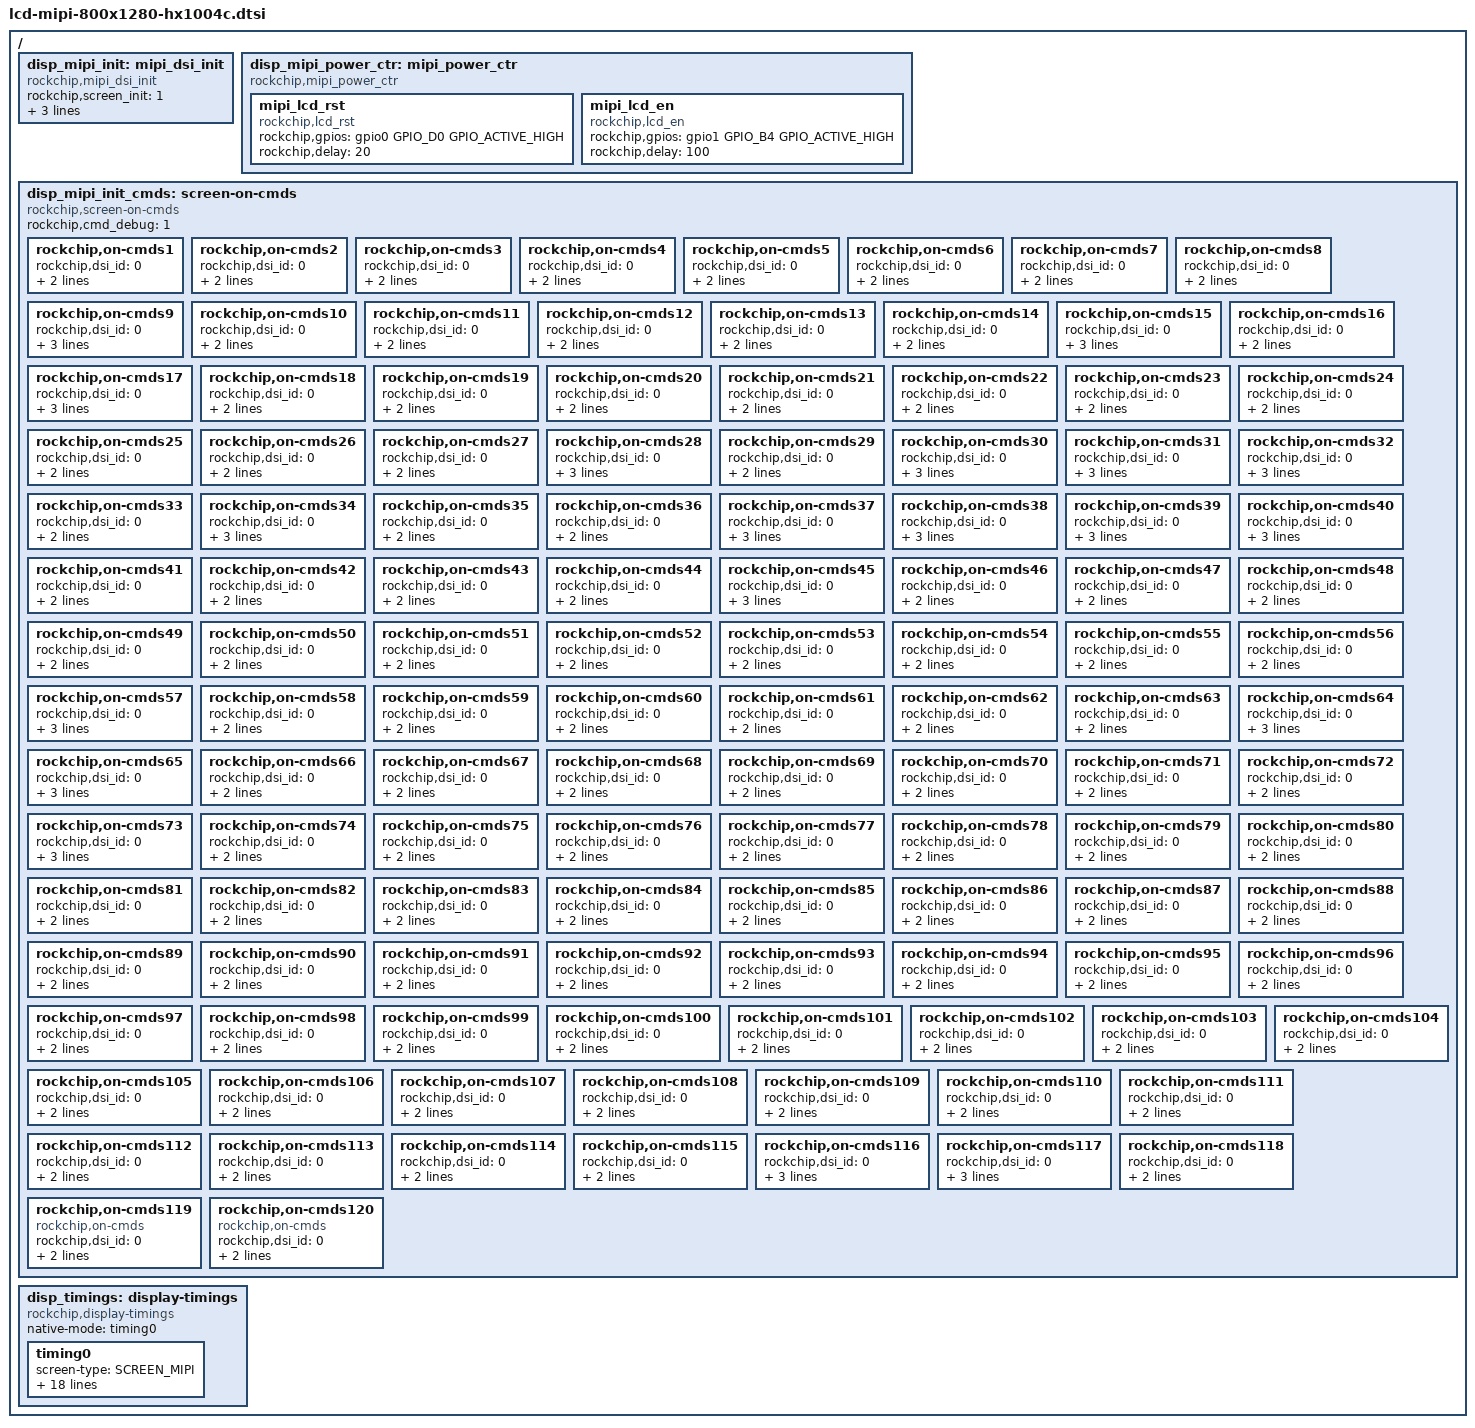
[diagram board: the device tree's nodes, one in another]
/*
 * Copyright (C) 2014 ROCKCHIP, Inc.
 * Licensed under GPLv2 or later.
 * arch/arm/boot/dts/lcd-mipi-1280x800-hx1004c.dtsi
 * author: chenyf@rock-chips.com
 * create date: 2018-11-21
 * lcd model: HX1004C
 * resolution: 800 x 1280
 * mipi channel: 
 */

/ {
		/* about mipi */
		disp_mipi_init: mipi_dsi_init{
					compatible = "rockchip,mipi_dsi_init";
					rockchip,screen_init	= <1>;
					rockchip,dsi_lane	= <4>;
					rockchip,dsi_hs_clk	= <528>;
					rockchip,mipi_dsi_num	= <1>;
		};
		disp_mipi_power_ctr: mipi_power_ctr {
					compatible = "rockchip,mipi_power_ctr";
					mipi_lcd_rst:mipi_lcd_rst{
							compatible = "rockchip,lcd_rst";
							rockchip,gpios = <&gpio0 GPIO_D0 GPIO_ACTIVE_HIGH>;
							rockchip,delay = <20>;
					};
					mipi_lcd_en:mipi_lcd_en {
							compatible = "rockchip,lcd_en";
							rockchip,gpios = <&gpio1 GPIO_B4 GPIO_ACTIVE_HIGH>;
							rockchip,delay = <100>;
					};
		};
		disp_mipi_init_cmds: screen-on-cmds {
					compatible = "rockchip,screen-on-cmds";
					rockchip,cmd_debug = <1>;
					
					#if 1
					rockchip,on-cmds1 {
							rockchip,dsi_id = <0>;
							rockchip,cmd = <0x39 0xFF 0xAA 0x55 0x25 0x01>;
							rockchip,cmd_delay = <0>;
					};
					rockchip,on-cmds2 {
							rockchip,dsi_id = <0>;
							rockchip,cmd = <0x15 0xFC 0x08>;
							rockchip,cmd_delay = <1>;
					};
					rockchip,on-cmds3 {
							rockchip,dsi_id = <0>;
							rockchip,cmd = <0x15 0xFC 0x00>;
							rockchip,cmd_delay = <1>;
					};
					rockchip,on-cmds4 {
							rockchip,dsi_id = <0>;
							rockchip,cmd = <0x15 0x6F 0x21>;
							rockchip,cmd_delay = <0>;
					};
					rockchip,on-cmds5 {
							rockchip,dsi_id = <0>;
							rockchip,cmd = <0x15 0xF7 0x01>;
							rockchip,cmd_delay = <1>;
					};
					rockchip,on-cmds6 {
							rockchip,dsi_id = <0>;
							rockchip,cmd = <0x15 0x6F 0x21>;
							rockchip,cmd_delay = <0>;
					};
					rockchip,on-cmds7 {
							rockchip,dsi_id = <0>;
							rockchip,cmd = <0x15 0xF7 0x00>;
							rockchip,cmd_delay = <0>;
					};
					rockchip,on-cmds8 {
							rockchip,dsi_id = <0>;
							rockchip,cmd = <0x39 0xFF 0xAA 0x55 0x25 0x00>;
							rockchip,cmd_delay = <0>;
					};
					rockchip,on-cmds9 {
							rockchip,dsi_id = <0>;
							rockchip,cmd = <0x39 0xF0 0x55 0xAA 0x52 0x08 0x00>;
							rockchip,cmd_delay = <0>;
					};
					rockchip,on-cmds10 {
							rockchip,dsi_id = <0>;
							rockchip,cmd = <0x39 0xB1 0x68 0x01>;
							rockchip,cmd_delay = <0>;
					};
					rockchip,on-cmds11 {
							rockchip,dsi_id = <0>;
							rockchip,cmd = <0x15 0xB6 0x08>;
							rockchip,cmd_delay = <0>;
					};
					rockchip,on-cmds12 {
							rockchip,dsi_id = <0>;
							rockchip,cmd = <0x39 0xB8 0x01 0x02 0x08>;
							rockchip,cmd_delay = <0>;
					};
					rockchip,on-cmds13 {
							rockchip,dsi_id = <0>;
							rockchip,cmd = <0x39 0xBB 0x44 0x44>;
							rockchip,cmd_delay = <0>;
					};
					rockchip,on-cmds14 {
							rockchip,dsi_id = <0>;
							rockchip,cmd = <0x39 0xBC 0x00 0x00>;
							rockchip,cmd_delay = <0>;
					};
					rockchip,on-cmds15 {
							rockchip,dsi_id = <0>;
							rockchip,cmd = <0x39 0xBD 0x02 0x68 0x10 0x10 0x00>;
							rockchip,cmd_delay = <0>;
					};
					rockchip,on-cmds16 {
							rockchip,dsi_id = <0>;
							rockchip,cmd = <0x15 0xC8 0x80>;
							rockchip,cmd_delay = <0>;
					};
					rockchip,on-cmds17 {
							rockchip,dsi_id = <0>;
							rockchip,cmd = <0x39 0xF0 0x55 0xAA 0x52 0x08 0x01>;
							rockchip,cmd_delay = <0>;
					};
					rockchip,on-cmds18 {
							rockchip,dsi_id = <0>;
							rockchip,cmd = <0x39 0xB3 0x29 0x29>;
							rockchip,cmd_delay = <0>;
					};
					rockchip,on-cmds19 {
							rockchip,dsi_id = <0>;
							rockchip,cmd = <0x39 0xB4 0x10 0x10>;
							rockchip,cmd_delay = <0>;
					};
					rockchip,on-cmds20 {
							rockchip,dsi_id = <0>;
							rockchip,cmd = <0x39 0xB5 0x05 0x05>;
							rockchip,cmd_delay = <0>;
					};
					rockchip,on-cmds21 {
							rockchip,dsi_id = <0>;
							rockchip,cmd = <0x39 0xB9 0x36 0x35>;
							rockchip,cmd_delay = <0>;
					};
					rockchip,on-cmds22 {
							rockchip,dsi_id = <0>;
							rockchip,cmd = <0x39 0xBA 0x25 0x25>;
							rockchip,cmd_delay = <0>;
					};
					rockchip,on-cmds23 {
							rockchip,dsi_id = <0>;
							rockchip,cmd = <0x39 0xBC 0x68 0x01>;
							rockchip,cmd_delay = <0>;
					};
					rockchip,on-cmds24 {
							rockchip,dsi_id = <0>;
							rockchip,cmd = <0x39 0xBD 0x68 0x01>;
							rockchip,cmd_delay = <0>;
					};
					rockchip,on-cmds25 {
							rockchip,dsi_id = <0>;
							rockchip,cmd = <0x15 0xBE 0x3B>;
							rockchip,cmd_delay = <0>;
					};
					rockchip,on-cmds26 {
							rockchip,dsi_id = <0>;
							rockchip,cmd = <0x15 0xC0 0x0C>;
							rockchip,cmd_delay = <0>;
					};
					rockchip,on-cmds27 {
							rockchip,dsi_id = <0>;
							rockchip,cmd = <0x15 0xCA 0x00>;
							rockchip,cmd_delay = <0>;
					};
					rockchip,on-cmds28 {
							rockchip,dsi_id = <0>;
							rockchip,cmd = <0x39 0xF0 0x55 0xAA 0x52 0x08 0x02>;
							rockchip,cmd_delay = <0>;
					};
					rockchip,on-cmds29 {
							rockchip,dsi_id = <0>;
							rockchip,cmd = <0x15 0xEE 0x01>;
							rockchip,cmd_delay = <0>;
					};
					rockchip,on-cmds30 {
							rockchip,dsi_id = <0>;
							rockchip,cmd = <0x39 0xB0 0x00 0x00 0x00 0x0C 0x00 0x22 0x00 0x35 0x00 0x47 0x00 0x68 0x00 0x85 0x00 0xB8>;
							rockchip,cmd_delay = <0>;
					};
					rockchip,on-cmds31 {
							rockchip,dsi_id = <0>;
							rockchip,cmd = <0x39 0xB1 0x00 0xE3 0x01 0x2B 0x01 0x67 0x01 0xC5 0x02 0x15 0x02 0x18 0x02 0x60 0x02 0xAA>;
							rockchip,cmd_delay = <0>;
					};
					rockchip,on-cmds32 {
							rockchip,dsi_id = <0>;
							rockchip,cmd = <0x39 0xB2 0x02 0xD9 0x03 0x1B 0x03 0x40 0x03 0x6D 0x03 0x8D 0x03 0xB4 0x03 0xCE 0x03 0xE5>;
							rockchip,cmd_delay = <0>;
					};
					rockchip,on-cmds33 {
							rockchip,dsi_id = <0>;
							rockchip,cmd = <0x39 0xB3 0x03 0xFB 0x03 0xFF>;
							rockchip,cmd_delay = <0>;
					};
					rockchip,on-cmds34 {
							rockchip,dsi_id = <0>;
							rockchip,cmd = <0x39 0xF0 0x55 0xAA 0x52 0x08 0x03>;
							rockchip,cmd_delay = <0>;
					};
					rockchip,on-cmds35 {
							rockchip,dsi_id = <0>;
							rockchip,cmd = <0x39 0xB0 0x00 0x00>;
							rockchip,cmd_delay = <0>;
					};
					rockchip,on-cmds36 {
							rockchip,dsi_id = <0>;
							rockchip,cmd = <0x39 0xB1 0x00 0x00>;
							rockchip,cmd_delay = <0>;
					};
					rockchip,on-cmds37 {
							rockchip,dsi_id = <0>;
							rockchip,cmd = <0x39 0xB2 0x05 0x00 0x17 0x00 0x00>;
							rockchip,cmd_delay = <0>;
					};
					rockchip,on-cmds38 {
							rockchip,dsi_id = <0>;
							rockchip,cmd = <0x39 0xB6 0x05 0x00 0x00 0x00 0x00>;
							rockchip,cmd_delay = <0>;
					};
					rockchip,on-cmds39 {
							rockchip,dsi_id = <0>;
							rockchip,cmd = <0x39 0xBA 0x53 0x00 0xA0 0x00 0x00>;
							rockchip,cmd_delay = <0>;
					};
					rockchip,on-cmds40 {
							rockchip,dsi_id = <0>;
							rockchip,cmd = <0x39 0xBB 0x53 0x00 0xA0 0x00 0x00>;
							rockchip,cmd_delay = <0>;
					};
					rockchip,on-cmds41 {
							rockchip,dsi_id = <0>;
							rockchip,cmd = <0x39 0xC0 0x00 0x00 0x00 0x00>;
							rockchip,cmd_delay = <0>;
					};
					rockchip,on-cmds42 {
							rockchip,dsi_id = <0>;
							rockchip,cmd = <0x39 0xC1 0x00 0x00 0x00 0x00>;
							rockchip,cmd_delay = <0>;
					};
					rockchip,on-cmds43 {
							rockchip,dsi_id = <0>;
							rockchip,cmd = <0x15 0xC4 0x60>;
							rockchip,cmd_delay = <0>;
					};
					rockchip,on-cmds44 {
							rockchip,dsi_id = <0>;
							rockchip,cmd = <0x15 0xC5 0xC0>;
							rockchip,cmd_delay = <0>;
					};
					rockchip,on-cmds45 {
							rockchip,dsi_id = <0>;
							rockchip,cmd = <0x39 0xF0 0x55 0xAA 0x52 0x08 0x05>;
							rockchip,cmd_delay = <0>;
					};
					rockchip,on-cmds46 {
							rockchip,dsi_id = <0>;
							rockchip,cmd = <0x39 0xB0 0x17 0x06>;
							rockchip,cmd_delay = <0>;
					};
					rockchip,on-cmds47 {
							rockchip,dsi_id = <0>;
							rockchip,cmd = <0x39 0xB1 0x17 0x06>;
							rockchip,cmd_delay = <0>;
					};
					rockchip,on-cmds48 {
							rockchip,dsi_id = <0>;
							rockchip,cmd = <0x39 0xB2 0x17 0x06>;
							rockchip,cmd_delay = <0>;
					};
					rockchip,on-cmds49 {
							rockchip,dsi_id = <0>;
							rockchip,cmd = <0x39 0xB3 0x17 0x06>;
							rockchip,cmd_delay = <0>;
					};
					rockchip,on-cmds50 {
							rockchip,dsi_id = <0>;
							rockchip,cmd = <0x39 0xB4 0x17 0x06>;
							rockchip,cmd_delay = <0>;
					};
					rockchip,on-cmds51 {
							rockchip,dsi_id = <0>;
							rockchip,cmd = <0x39 0xB5 0x17 0x06>;
							rockchip,cmd_delay = <0>;
					};
					rockchip,on-cmds52 {
							rockchip,dsi_id = <0>;
							rockchip,cmd = <0x15 0xB8 0x0C>;
							rockchip,cmd_delay = <0>;
					};
					rockchip,on-cmds53 {
							rockchip,dsi_id = <0>;
							rockchip,cmd = <0x15 0xB9 0x00>;
							rockchip,cmd_delay = <0>;
					};
					rockchip,on-cmds54 {
							rockchip,dsi_id = <0>;
							rockchip,cmd = <0x15 0xBA 0x00>;
							rockchip,cmd_delay = <0>;
					};
					rockchip,on-cmds55 {
							rockchip,dsi_id = <0>;
							rockchip,cmd = <0x15 0xBB 0x0A>;
							rockchip,cmd_delay = <0>;
					};
					rockchip,on-cmds56 {
							rockchip,dsi_id = <0>;
							rockchip,cmd = <0x15 0xBC 0x02>;
							rockchip,cmd_delay = <0>;
					};
					rockchip,on-cmds57 {
							rockchip,dsi_id = <0>;
							rockchip,cmd = <0x39 0xBD 0x03 0x01 0x01 0x03 0x03>;
							rockchip,cmd_delay = <0>;
					};
					rockchip,on-cmds58 {
							rockchip,dsi_id = <0>;
							rockchip,cmd = <0x15 0xC0 0x07>;
							rockchip,cmd_delay = <0>;
					};
					rockchip,on-cmds59 {
							rockchip,dsi_id = <0>;
							rockchip,cmd = <0x15 0xC4 0xA2>;
							rockchip,cmd_delay = <0>;
					};
					rockchip,on-cmds60 {
							rockchip,dsi_id = <0>;
							rockchip,cmd = <0x39 0xC8 0x03 0x20>;
							rockchip,cmd_delay = <0>;
					};
					rockchip,on-cmds61 {
							rockchip,dsi_id = <0>;
							rockchip,cmd = <0x39 0xC9 0x01 0x21>;
							rockchip,cmd_delay = <0>;
					};
					rockchip,on-cmds62 {
							rockchip,dsi_id = <0>;
							rockchip,cmd = <0x39 0xCC 0x00 0x00 0x01>;
							rockchip,cmd_delay = <0>;
					};
					rockchip,on-cmds63 {
							rockchip,dsi_id = <0>;
							rockchip,cmd = <0x39 0xCD 0x00 0x00 0x01>;
							rockchip,cmd_delay = <0>;
					};
					rockchip,on-cmds64 {
							rockchip,dsi_id = <0>;
							rockchip,cmd = <0x39 0xD1 0x00 0x04 0xFC 0x07 0x14>;
							rockchip,cmd_delay = <0>;
					};
					rockchip,on-cmds65 {
							rockchip,dsi_id = <0>;
							rockchip,cmd = <0x39 0xD2 0x10 0x05 0x00 0x03 0x16>;
							rockchip,cmd_delay = <0>;
					};
					rockchip,on-cmds66 {
							rockchip,dsi_id = <0>;
							rockchip,cmd = <0x15 0xE5 0x06>;
							rockchip,cmd_delay = <0>;
					};
					rockchip,on-cmds67 {
							rockchip,dsi_id = <0>;
							rockchip,cmd = <0x15 0xE6 0x06>;
							rockchip,cmd_delay = <0>;
					};
					rockchip,on-cmds68 {
							rockchip,dsi_id = <0>;
							rockchip,cmd = <0x15 0xE7 0x06>;
							rockchip,cmd_delay = <0>;
					};
					rockchip,on-cmds69 {
							rockchip,dsi_id = <0>;
							rockchip,cmd = <0x15 0xE8 0x06>;
							rockchip,cmd_delay = <0>;
					};
					rockchip,on-cmds70 {
							rockchip,dsi_id = <0>;
							rockchip,cmd = <0x15 0xE9 0x06>;
							rockchip,cmd_delay = <0>;
					};
					rockchip,on-cmds71 {
							rockchip,dsi_id = <0>;
							rockchip,cmd = <0x15 0xEA 0x06>;
							rockchip,cmd_delay = <0>;
					};
					rockchip,on-cmds72 {
							rockchip,dsi_id = <0>;
							rockchip,cmd = <0x15 0xED 0x30>;
							rockchip,cmd_delay = <0>;
					};
					rockchip,on-cmds73 {
							rockchip,dsi_id = <0>;
							rockchip,cmd = <0x39 0xF0 0x55 0xAA 0x52 0x08 0x06>;
							rockchip,cmd_delay = <0>;
					};
					rockchip,on-cmds74 {
							rockchip,dsi_id = <0>;
							rockchip,cmd = <0x39 0xB0 0x17 0x11>;
							rockchip,cmd_delay = <0>;
					};
					rockchip,on-cmds75 {
							rockchip,dsi_id = <0>;
							rockchip,cmd = <0x39 0xB1 0x16 0x10>;
							rockchip,cmd_delay = <0>;
					};
					rockchip,on-cmds76 {
							rockchip,dsi_id = <0>;
							rockchip,cmd = <0x39 0xB2 0x12 0x18>;
							rockchip,cmd_delay = <0>;
					};
					rockchip,on-cmds77 {
							rockchip,dsi_id = <0>;
							rockchip,cmd = <0x39 0xB3 0x13 0x19>;
							rockchip,cmd_delay = <0>;
					};
					rockchip,on-cmds78 {
							rockchip,dsi_id = <0>;
							rockchip,cmd = <0x39 0xB4 0x00 0x31>;
							rockchip,cmd_delay = <0>;
					};
					rockchip,on-cmds79 {
							rockchip,dsi_id = <0>;
							rockchip,cmd = <0x39 0xB5 0x31 0x34>;
							rockchip,cmd_delay = <0>;
					};
					rockchip,on-cmds80 {
							rockchip,dsi_id = <0>;
							rockchip,cmd = <0x39 0xB6 0x34 0x29>;
							rockchip,cmd_delay = <0>;
					};
					rockchip,on-cmds81 {
							rockchip,dsi_id = <0>;
							rockchip,cmd = <0x39 0xB7 0x2A 0x33>;
							rockchip,cmd_delay = <0>;
					};
					rockchip,on-cmds82 {
							rockchip,dsi_id = <0>;
							rockchip,cmd = <0x39 0xB8 0x2E 0x2D>;
							rockchip,cmd_delay = <0>;
					};
					rockchip,on-cmds83 {
							rockchip,dsi_id = <0>;
							rockchip,cmd = <0x39 0xB9 0x08 0x34>;
							rockchip,cmd_delay = <0>;
					};
					rockchip,on-cmds84 {
							rockchip,dsi_id = <0>;
							rockchip,cmd = <0x39 0xBA 0x34 0x08>;
							rockchip,cmd_delay = <0>;
					};
					rockchip,on-cmds85 {
							rockchip,dsi_id = <0>;
							rockchip,cmd = <0x39 0xBB 0x2D 0x2E>;
							rockchip,cmd_delay = <0>;
					};
					rockchip,on-cmds86 {
							rockchip,dsi_id = <0>;
							rockchip,cmd = <0x39 0xBC 0x34 0x2A>;
							rockchip,cmd_delay = <0>;
					};
					rockchip,on-cmds87 {
							rockchip,dsi_id = <0>;
							rockchip,cmd = <0x39 0xBD 0x29 0x34>;
							rockchip,cmd_delay = <0>;
					};
					rockchip,on-cmds88 {
							rockchip,dsi_id = <0>;
							rockchip,cmd = <0x39 0xBE 0x34 0x31>;
							rockchip,cmd_delay = <0>;
					};
					rockchip,on-cmds89 {
							rockchip,dsi_id = <0>;
							rockchip,cmd = <0x39 0xBF 0x31 0x00>;
							rockchip,cmd_delay = <0>;
					};
					rockchip,on-cmds90 {
							rockchip,dsi_id = <0>;
							rockchip,cmd = <0x39 0xC0 0x19 0x13>;
							rockchip,cmd_delay = <0>;
					};
					rockchip,on-cmds91 {
							rockchip,dsi_id = <0>;
							rockchip,cmd = <0x39 0xC1 0x18 0x12>;
							rockchip,cmd_delay = <0>;
					};
					rockchip,on-cmds92 {
							rockchip,dsi_id = <0>;
							rockchip,cmd = <0x39 0xC2 0x10 0x16>;
							rockchip,cmd_delay = <0>;
					};
					rockchip,on-cmds93 {
							rockchip,dsi_id = <0>;
							rockchip,cmd = <0x39 0xC3 0x11 0x17>;
							rockchip,cmd_delay = <0>;
					};
					rockchip,on-cmds94 {
							rockchip,dsi_id = <0>;
							rockchip,cmd = <0x39 0xE5 0x34 0x34>;
							rockchip,cmd_delay = <0>;
					};
					rockchip,on-cmds95 {
							rockchip,dsi_id = <0>;
							rockchip,cmd = <0x39 0xC4 0x12 0x18>;
							rockchip,cmd_delay = <0>;
					};
					rockchip,on-cmds96 {
							rockchip,dsi_id = <0>;
							rockchip,cmd = <0x39 0xC5 0x13 0x19>;
							rockchip,cmd_delay = <0>;
					};
					rockchip,on-cmds97 {
							rockchip,dsi_id = <0>;
							rockchip,cmd = <0x39 0xC6 0x17 0x11>;
							rockchip,cmd_delay = <0>;
					};
					rockchip,on-cmds98 {
							rockchip,dsi_id = <0>;
							rockchip,cmd = <0x39 0xC7 0x16 0x10>;
							rockchip,cmd_delay = <0>;
					};
					rockchip,on-cmds99 {
							rockchip,dsi_id = <0>;
							rockchip,cmd = <0x39 0xC8 0x08 0x31>;
							rockchip,cmd_delay = <0>;
					};
					rockchip,on-cmds100 {
							rockchip,dsi_id = <0>;
							rockchip,cmd = <0x39 0xC9 0x31 0x34>;
							rockchip,cmd_delay = <0>;
					};
					rockchip,on-cmds101 {
							rockchip,dsi_id = <0>;
							rockchip,cmd = <0x39 0xCA 0x34 0x29>;
							rockchip,cmd_delay = <0>;
					};
					rockchip,on-cmds102 {
							rockchip,dsi_id = <0>;
							rockchip,cmd = <0x39 0xCB 0x2A 0x33>;
							rockchip,cmd_delay = <0>;
					};
					rockchip,on-cmds103 {
							rockchip,dsi_id = <0>;
							rockchip,cmd = <0x39 0xCC 0x2D 0x2E>;
							rockchip,cmd_delay = <0>;
					};
					rockchip,on-cmds104 {
							rockchip,dsi_id = <0>;
							rockchip,cmd = <0x39 0xCD 0x00 0x34>;
							rockchip,cmd_delay = <0>;
					};
					rockchip,on-cmds105 {
							rockchip,dsi_id = <0>;
							rockchip,cmd = <0x39 0xCE 0x34 0x00>;
							rockchip,cmd_delay = <0>;
					};
					rockchip,on-cmds106 {
							rockchip,dsi_id = <0>;
							rockchip,cmd = <0x39 0xCF 0x2E 0x2D>;
							rockchip,cmd_delay = <0>;
					};
					rockchip,on-cmds107 {
							rockchip,dsi_id = <0>;
							rockchip,cmd = <0x39 0xD0 0x34 0x2A>;
							rockchip,cmd_delay = <0>;
					};
					rockchip,on-cmds108 {
							rockchip,dsi_id = <0>;
							rockchip,cmd = <0x39 0xD1 0x29 0x34>;
							rockchip,cmd_delay = <0>;
					};
					rockchip,on-cmds109 {
							rockchip,dsi_id = <0>;
							rockchip,cmd = <0x39 0xD2 0x34 0x31>;
							rockchip,cmd_delay = <0>;
					};
					rockchip,on-cmds110 {
							rockchip,dsi_id = <0>;
							rockchip,cmd = <0x39 0xD3 0x31 0x08>;
							rockchip,cmd_delay = <0>;
					};
					rockchip,on-cmds111 {
							rockchip,dsi_id = <0>;
							rockchip,cmd = <0x39 0xD4 0x10 0x16>;
							rockchip,cmd_delay = <0>;
					};
					rockchip,on-cmds112 {
							rockchip,dsi_id = <0>;
							rockchip,cmd = <0x39 0xD5 0x11 0x17>;
							rockchip,cmd_delay = <0>;
					};
					rockchip,on-cmds113 {
							rockchip,dsi_id = <0>;
							rockchip,cmd = <0x39 0xD6 0x19 0x13>;
							rockchip,cmd_delay = <0>;
					};
					rockchip,on-cmds114 {
							rockchip,dsi_id = <0>;
							rockchip,cmd = <0x39 0xD7 0x18 0x12>;
							rockchip,cmd_delay = <0>;
					};
					rockchip,on-cmds115 {
							rockchip,dsi_id = <0>;
							rockchip,cmd = <0x39 0xE6 0x34 0x34>;
							rockchip,cmd_delay = <0>;
					};
					rockchip,on-cmds116 {
							rockchip,dsi_id = <0>;
							rockchip,cmd = <0x39 0xD8 0x00 0x00 0x00 0x00 0x00>;
							rockchip,cmd_delay = <0>;
					};
					rockchip,on-cmds117 {
							rockchip,dsi_id = <0>;
							rockchip,cmd = <0x39 0xD9 0x00 0x00 0x00 0x00 0x00>;
							rockchip,cmd_delay = <0>;
					};
					rockchip,on-cmds118 {
							rockchip,dsi_id = <0>;
							rockchip,cmd = <0x15 0xE7 0x00>;
							rockchip,cmd_delay = <0>;
					};
					#endif
				
					rockchip,on-cmds119 {
							compatible = "rockchip,on-cmds";
							rockchip,dsi_id = <0>;
							rockchip,cmd = <0x05 0x11>;
							rockchip,cmd_delay = <120>;
					};
				
					
						rockchip,on-cmds120 {
							compatible = "rockchip,on-cmds";
							rockchip,dsi_id = <0>;
							rockchip,cmd = <0x05 0x29>;
							rockchip,cmd_delay = <100>;
					};
					
					
		};


		disp_timings: display-timings {
                        native-mode = <&timing0>;
                        compatible = "rockchip,display-timings";
                        timing0: timing0 {
				screen-type = <SCREEN_MIPI>;
				lvds-format = <LVDS_8BIT_1>;
				out-face    = <OUT_P888>;
				clock-frequency = <71000000>;
				hactive = <800>;
				vactive = <1280>;
				hback-porch = <60>;
				hfront-porch = <24>;
				vback-porch = <8>;
				vfront-porch = <8>;
				hsync-len = <4>;
				vsync-len = <4>;

				hsync-active = <0>;
				vsync-active = <0>;
				de-active = <0>;
				pixelclk-active = <0>;
				swap-rb = <0>;
				swap-rg = <1>;
				swap-gb = <0>;
                     	};
               };
};
